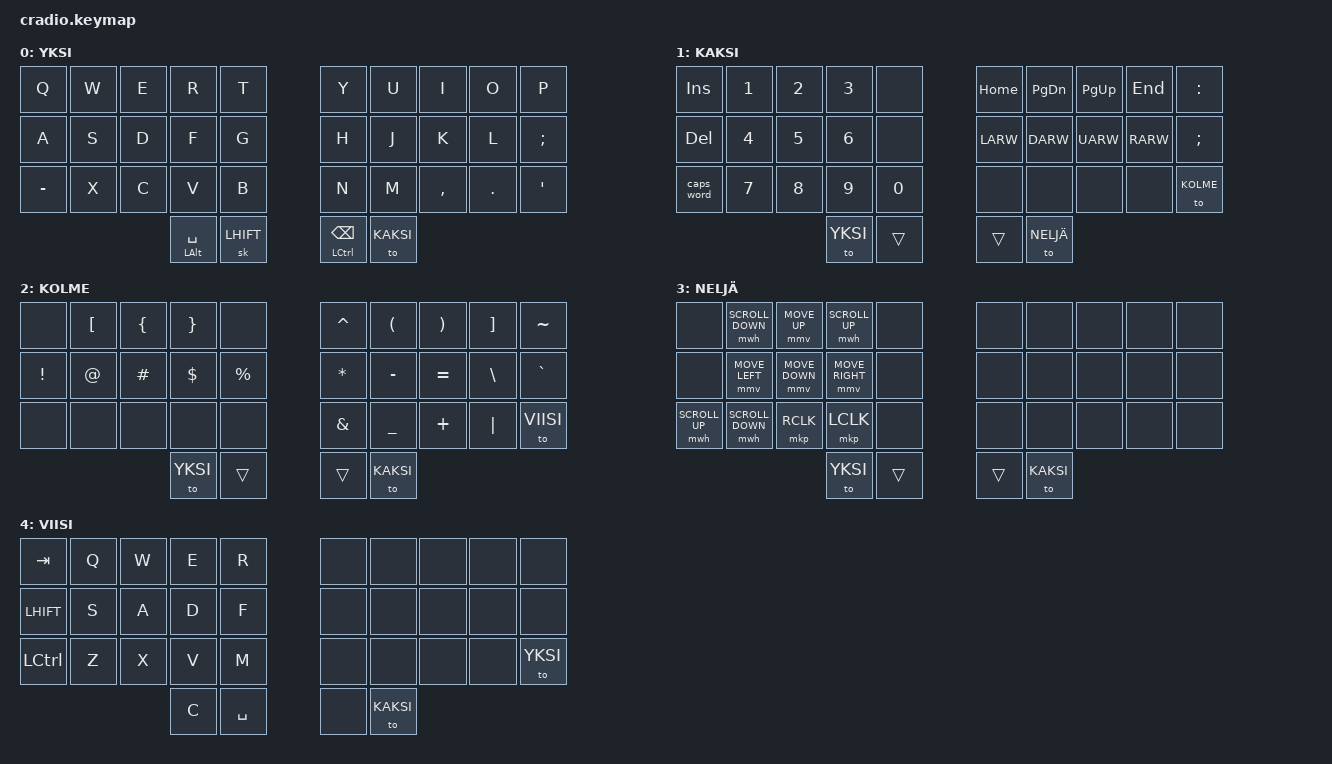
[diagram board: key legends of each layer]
/*
 * Copyright (c) 2020 The ZMK Contributors
 *
 * SPDX-License-Identifier: MIT
 */

#define YKSI 0
#define KAKSI 1
#define KOLME 2
#define NELJÄ 3
#define VIISI 4

#include <dt-bindings/zmk/outputs.h>
#include <dt-bindings/zmk/bt.h>
#include <behaviors.dtsi>
#include <dt-bindings/zmk/keys.h>
#include <dt-bindings/zmk/bt.h>
#include <dt-bindings/zmk/mouse.h>


&mt {
    flavor = "tap-preferred";
    tapping_term_ms = <200>;
};


/ { 
    combos {
        compatible = "zmk,combos";
        combo_esc { 
            timeout-ms = <50>;
            key-positions = <21 22>;
            bindings = <&kp ESC>;
        };
        combo_3 {
            timeout-ms = <50>;
            key-positions = <7 8>;
            bindings = <&to 3>;
        };
        combo_ent {
            timeout-ms = <50>;
	    key-positions = <27 28>;
            bindings = <&kp RET>;
        };
        combo_1 {
            timeout-ms = <50>;
	    key-positions = <30 33>;
            bindings = <&to 1>;
        };
        combo_1_high {
            timeout-ms = <50>;
	    key-positions = <24 25>;
            bindings = <&to 1>;
        };
        combo_g {
            timeout-ms = <15>;
	    key-positions = <12 13>;
            bindings = <&kp G>;
            layers = <0>;
        };
        combo_j {
            timeout-ms = <50>;
	    key-positions = <22 23>;
            bindings = <&kp J>;
            layers = <0>;
        };
        combo_p {
            timeout-ms = <15>;
	    key-positions = <16 17>;
            bindings = <&kp P>;
            layers = <0>;
        };
        combo_b {
            timeout-ms = <50>;
	    key-positions = <26 27>;
            bindings = <&kp B>;
            layers = <0>;
        };
        combo_scol {
            timeout-ms = <50>;
	    key-positions = <8 9>;
            bindings = <&kp SEMI>;
            layers = <0>;
        };
        combo_com {
            timeout-ms = <50>;
	    key-positions = <20 21>;
            bindings = <&kp COMMA>;
            layers = <0>;
        };
        combo_minus {
            timeout-ms = <50>;
	    key-positions = <0 1>;
            bindings = <&kp MINUS>;
            layers = <0>;
        };
        combo_slsh {
            timeout-ms = <50>;
	    key-positions = <28 29>;
            bindings = <&kp SLASH>;
            layers = <0>;
        };
        combo_sqt {
            timeout-ms = <50>;
	    key-positions = <12 13>;
            bindings = <&kp SQT>;
            layers = <1>;
        };
        combo_dqt {
            timeout-ms = <50>;
	    key-positions = <22 23>;
            bindings = <&kp DQT>;
            layers = <1>;
        };
        combo_bslh {
            timeout-ms = <50>;
	    key-positions = <16 17>;
            bindings = <&kp BSLH>;
            layers = <1>;
        };
        combo_lbkt {
            timeout-ms = <50>;
	    key-positions = <26 27>;
            bindings = <&kp LBKT>;
            layers = <1>;
        };
        combo_n0 {
            timeout-ms = <50>;
	    key-positions = <26 27>;
            bindings = <&kp N0>;
            layers = <2>;
        };
        combo_lalt {
            timeout-ms = <50>;
	    key-positions = <12 13>;
            bindings = <&kp LALT>;
            layers = <3>;
        };
        combo_del {
            timeout-ms = <50>;
	    key-positions = <22 23>;
            bindings = <&kp DEL>;
            layers = <3>;
        };
        combo_left {
            timeout-ms = <50>;
	    key-positions = <16 17>;
            bindings = <&kp LEFT>;
            layers = <3>;
        };
        combo_lclk {
            timeout-ms = <50>;
	    key-positions = <26 27>;
            bindings = <&mkp LCLK>;
            layers = <3>;
        };
    };

    behaviors {
        hm: homerow_mods {
            compatible = "zmk,behavior-hold-tap";
            label = "HOMEROW_MODS";
            #binding-cells = <2>;
            tapping-term-ms = <200>;
            quick_tap_ms = <0>;
            flavor = "tap-preferred";
            bindings = <&kp>, <&kp>;
        };
        hs: homerow_shifts {
            compatible = "zmk,behavior-hold-tap";
            label = "HOMEROW_SHIFTS";
            #binding-cells = <2>;
            tapping-term-ms = <150>;
            quick_tap_ms = <0>;
            flavor = "balanced";
            bindings = <&kp>, <&kp>;
        };
        hsl: homerow_shifts_layer {
            compatible = "zmk,behavior-hold-tap";
            label = "HOMEROW_SHIFTS_LAYER";
            #binding-cells = <2>;
            tapping-term-ms = <150>;
            quick_tap_ms = <0>;
            flavor = "balanced";
            bindings = <&kp>, <&to>;
        };
	td: tapdance {
            compatible = "zmk,behavior-hold-tap";
            label = "TAPDANCE";
            #binding-cells = <2>;
            tapping-term-ms = <150>;
            quick_tap_ms = <0>;
            flavor = "tap-preferred";
            bindings = <&kp>, <&kp>;
        };
	bl: layertap {
            compatible = "zmk,behavior-hold-tap";
            label = "LAYERTAP";
            #binding-cells = <2>;
            tapping-term-ms = <150>;
            quick_tap_ms = <0>;
            flavor = "tap-preferred";
            bindings = <&to>, <&kp>;
        };
        skq: sticky_key_quick_release {
        compatible = "zmk,behavior-sticky-key";
        label = "STICKY_KEY_QUICK_RELEASE";
        #binding-cells = <1>;
        bindings = <&kp>;
        release-after-ms = <1000>;
        quick-release;
        ignore-modifiers;
      };
    };

        keymap {
        compatible = "zmk,keymap";
        YKSI {
            bindings = <
        //╭──────────┬──────────┬──────────┬──────────┬──────────╮   ╭──────────┬──────────┬──────────┬──────────┬──────────╮
        //│  Q       │  W       │  E       │  R       │  T       │   │  Y       │  U       │  I       │  O       │  P       │
            &kp Q      &kp W      &kp E      &kp R      &kp T          &kp Y      &kp U      &kp I      &kp O      &kp P
        //├──────────┼──────────┼──────────┼──────────┼──────────┤   ├──────────┼──────────┼──────────┼──────────┼──────────┤
        //│  A       │  S       │  D       │  F       │  G       │   │  H       │  J       │  K       │  L       │ ; : (ö)  │
              &kp A     &kp S      &kp D      &kp F      &kp G          &kp H      &kp J     &kp K,      &kp L,     &kp SEMI)
        //├──────────┼──────────┼──────────┼──────────┼──────────┤   ├──────────┼──────────┼──────────┼──────────┼──────────┤
        //│  -       │  X       │  C       │  V       │  B       │   │  N       │  M       │ , <      │ . >      │ ' "  (ä) |
            &kp MINUS   &kp X      &kp C      &kp V      &kp B          &kp N      &kp M      &kp COMMA  &kp DOT    &kp SQT
        //╰──────────┴──────────┴──────────┼──────────┼──────────┤   ├──────────┼──────────┼──────────┴──────────┴──────────╯
                                         &mt LALT SPACE &sk LHIFT &mt LCTRL BSPC &to KAKSI
        //                                 ╰──────────┴──────────╯   ╰──────────┴──────────╯
            >;
        };

        KAKSI {
            bindings = <
        //╭──────────┬──────────┬──────────┬──────────┬──────────╮   ╭──────────┬──────────┬──────────┬──────────┬──────────╮
        //│ INSERT   │  1       │  2       │  3       │          │   │ HOME     │ PAGE DN  │ PAGE UP  │ END      │  :       │
            &kp INS    &kp N1     &kp N2     &kp N3     &none          &kp HOME   &kp PG_DN  &kp PG_UP  &kp END    &kp COLON
        //├──────────┼──────────┼──────────┼──────────┼──────────┤   ├──────────┼──────────┼──────────┼──────────┼──────────┤
        //│ DELETE   │  4       │  5       │  6       │          │   │ LEFT     │ DOWN     │ UP       │ RIGHT    │  ;       │
            &kp DEL    &kp N4     &kp N5     &kp N6     &none         &kp LARW   &kp DARW   &kp UARW   &kp RARW   &kp SEMI
        //├──────────┼──────────┼──────────┼──────────┼──────────┤   ├──────────┼──────────┼──────────┼──────────┼──────────┤
        //│ CAPS     │  7       │  8       │  9       │  0       │   │          │          │          │          │          │
           &caps_word  &kp N7     &kp N8     &kp N9     &kp N0        &none      &none      &none      &none      &to KOLME      
        //╰──────────┴──────────┴──────────┼──────────┼──────────┤   ├──────────┼──────────┼──────────┴──────────┴──────────╯
                                             &to YKSI   &trans        &trans     &to NELJÄ
        //                                 ╰──────────┴──────────╯   ╰──────────┴──────────╯
            >;
        };

        KOLME {
            bindings = <
        //╭──────────┬──────────┬──────────┬──────────┬──────────╮   ╭──────────┬──────────┬──────────┬──────────┬──────────╮
        //│          │  [       │  {       │  }       │          │   │  ^       │  (       │  )       │  ]       │  ~       │
           &none      &kp LBKT   &kp LBRC   &kp RBRC   &none          &kp CARET  &kp LPAR   &kp RPAR   &kp RBKT   &kp TILDE
        //├──────────┼──────────┼──────────┼──────────┼──────────┤   ├──────────┼──────────┼──────────┼──────────┼──────────┤
        //│  !       │  @       │  #       │  $       │  %       │   │  *       │  -       │  =       │  \       │  `       │
            &kp EXCL   &kp AT     &kp HASH   &kp DLLR   &kp PRCNT      &kp ASTRK  &kp MINUS  &kp EQUAL  &kp BSLH   &kp GRAVE
        //├──────────┼──────────┼──────────┼──────────┼──────────┤   ├──────────┼──────────┼──────────┼──────────┼──────────┤
        //│          │          │          │          │          │   │  &       │  _       │  +       │  │       │          │
           &none      &none      &none      &none      &none          &kp AMPS   &kp UNDER  &kp PLUS   &kp PIPE   &to VIISI      
        //╰──────────┴──────────┴──────────┼──────────┼──────────┤   ├──────────┼──────────┼──────────┴──────────┴──────────╯
                                             &to YKSI  &trans         &trans     &to KAKSI
        //                                 ╰──────────┴──────────╯   ╰──────────┴──────────╯
            >;
        };

       NELJÄ {
            bindings = <
        //╭──────────┬──────────┬──────────┬──────────┬──────────╮   ╭──────────┬──────────┬──────────┬──────────┬──────────╮
        //│          │          │          │          │          │   │          │          │          │          │          │
         &none &mwh SCROLL_DOWN &mmv MOVE_UP &mwh SCROLL_UP &none     &none      &none      &none      &none      &none                                                                                                         
        //├──────────┼──────────┼──────────┼──────────┼──────────┤   ├──────────┼──────────┼──────────┼──────────┼──────────┤
        //│          │          │          │          │          │   │          │          │          │          │          │
         &none &mmv MOVE_LEFT &mmv MOVE_DOWN &mmv MOVE_RIGHT &none    &none      &none      &none      &none      &none       
        //├──────────┼──────────┼──────────┼──────────┼──────────┤   ├──────────┼──────────┼──────────┼──────────┼──────────┤
        //│          │          │          │          │          │   │          │          │          │          │          │
         &mwh SCROLL_UP &mwh SCROLL_DOWN &mkp RCLK &mkp LCLK &none    &none      &none      &none      &none      &none        
        //╰──────────┴──────────┴──────────┼──────────┼──────────┤   ├──────────┼──────────┼──────────┴──────────┴──────────╯
                                            &to YKSI   &trans         &trans     &to KAKSI      
        //                                 ╰──────────┴──────────╯   ╰──────────┴──────────╯
            >;
        };

        VIISI {
            bindings = <
        //╭──────────┬──────────┬──────────┬──────────┬──────────╮   ╭──────────┬──────────┬──────────┬──────────┬──────────╮
        //│          │          │          │          │          │   │          │          │          │          │          │
           &kp TAB    &kp Q      &kp W      &kp E      &kp R          &none      &none      &none      &none      &none                                                                
        //├──────────┼──────────┼──────────┼──────────┼──────────┤   ├──────────┼──────────┼──────────┼──────────┼──────────┤
        //│          │          │          │          │          │   │          │          │          │          │          │
           &kp LHIFT  &kp S      &kp A      &kp D      &kp F          &none      &none      &none      &none      &none
        //├──────────┼──────────┼──────────┼──────────┼──────────┤   ├──────────┼──────────┼──────────┼──────────┼──────────┤
        //│          │          │          │          │          │   │          │          │          │          │          │
           &kp LCTRL  &kp Z      &kp X      &kp V      &kp M          &none      &none      &none      &none      &to YKSI
        //╰──────────┴──────────┴──────────┼──────────┼──────────┤   ├──────────┼──────────┼──────────┴──────────┴──────────╯
                                            &kp C      &kp SPACE      &none      &to KAKSI
        //                                 ╰──────────┴──────────╯   ╰──────────┴──────────╯
            >;
        };

    };
};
